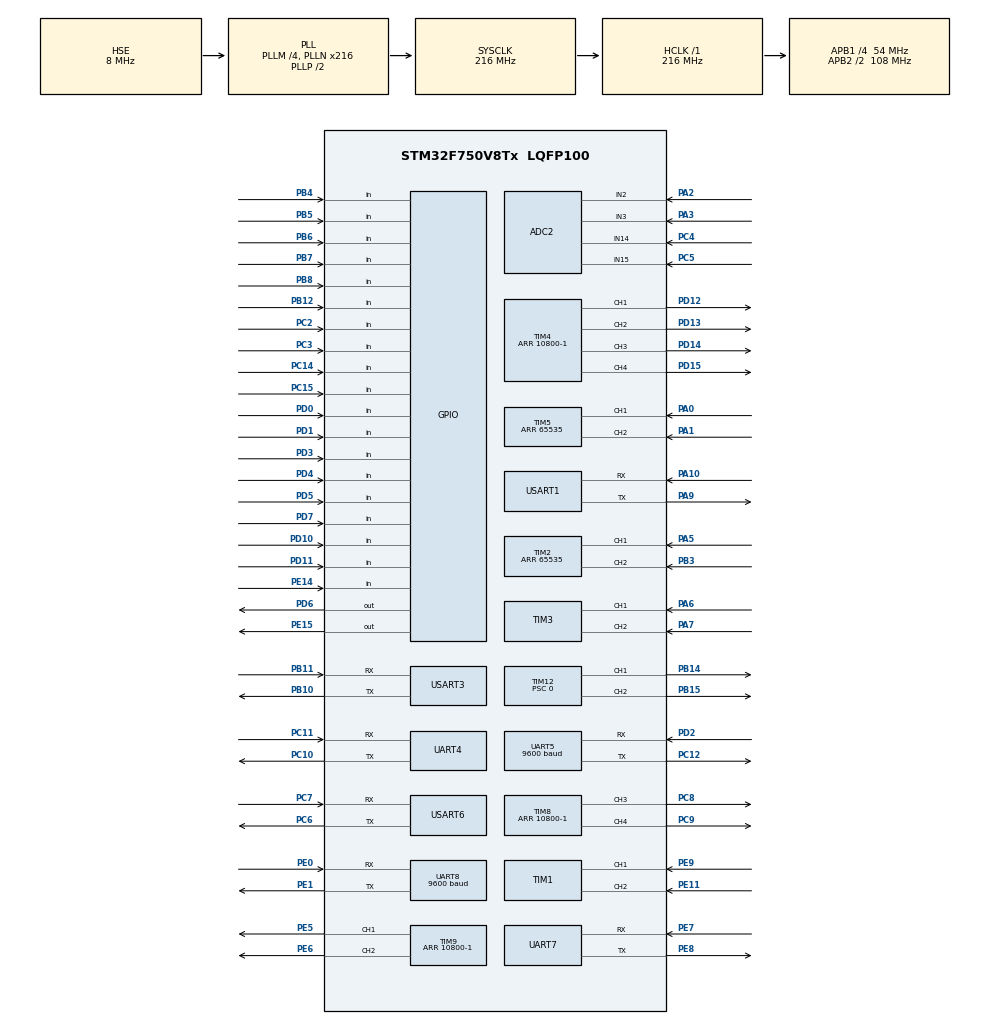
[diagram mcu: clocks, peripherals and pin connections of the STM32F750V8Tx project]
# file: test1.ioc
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ADC2.Channel-1\#ChannelRegularConversion=ADC_CHANNEL_2
ADC2.Channel-2\#ChannelRegularConversion=ADC_CHANNEL_3
ADC2.Channel-3\#ChannelRegularConversion=ADC_CHANNEL_14
ADC2.Channel-4\#ChannelRegularConversion=ADC_CHANNEL_15
ADC2.ContinuousConvMode=ENABLE
ADC2.DMAContinuousRequests=ENABLE
ADC2.NbrOfConversion=4
ADC2.NbrOfConversionFlag=1
ADC2.Rank-1\#ChannelRegularConversion=1
ADC2.Rank-2\#ChannelRegularConversion=2
ADC2.Rank-3\#ChannelRegularConversion=3
ADC2.Rank-4\#ChannelRegularConversion=4
ADC2.SamplingTime-1\#ChannelRegularConversion=ADC_SAMPLETIME_480CYCLES
ADC2.SamplingTime-2\#ChannelRegularConversion=ADC_SAMPLETIME_480CYCLES
ADC2.SamplingTime-3\#ChannelRegularConversion=ADC_SAMPLETIME_480CYCLES
ADC2.SamplingTime-4\#ChannelRegularConversion=ADC_SAMPLETIME_480CYCLES
CORTEX_M7.default_mode_Activation=1
Dma.ADC2.3.Direction=DMA_PERIPH_TO_MEMORY
Dma.ADC2.3.FIFOMode=DMA_FIFOMODE_DISABLE
Dma.ADC2.3.Instance=DMA2_Stream2
Dma.ADC2.3.MemDataAlignment=DMA_MDATAALIGN_HALFWORD
Dma.ADC2.3.MemInc=DMA_MINC_ENABLE
Dma.ADC2.3.Mode=DMA_CIRCULAR
Dma.ADC2.3.PeriphDataAlignment=DMA_PDATAALIGN_HALFWORD
Dma.ADC2.3.PeriphInc=DMA_PINC_DISABLE
Dma.ADC2.3.Priority=DMA_PRIORITY_VERY_HIGH
Dma.Request0=USART3_RX
Dma.Request1=UART4_RX
Dma.Request2=UART4_TX
Dma.Request3=ADC2
Dma.UART4_RX.1.Direction=DMA_PERIPH_TO_MEMORY
Dma.UART4_RX.1.FIFOMode=DMA_FIFOMODE_DISABLE
Dma.UART4_RX.1.Instance=DMA1_Stream2
Dma.UART4_RX.1.MemDataAlignment=DMA_MDATAALIGN_BYTE
Dma.UART4_RX.1.MemInc=DMA_MINC_ENABLE
Dma.UART4_RX.1.Mode=DMA_NORMAL
Dma.UART4_RX.1.PeriphDataAlignment=DMA_PDATAALIGN_BYTE
Dma.UART4_RX.1.PeriphInc=DMA_PINC_DISABLE
Dma.UART4_RX.1.Priority=DMA_PRIORITY_HIGH
Dma.UART4_TX.2.Direction=DMA_MEMORY_TO_PERIPH
Dma.UART4_TX.2.FIFOMode=DMA_FIFOMODE_DISABLE
Dma.UART4_TX.2.Instance=DMA1_Stream4
Dma.UART4_TX.2.MemDataAlignment=DMA_MDATAALIGN_BYTE
Dma.UART4_TX.2.MemInc=DMA_MINC_ENABLE
Dma.UART4_TX.2.Mode=DMA_NORMAL
Dma.UART4_TX.2.PeriphDataAlignment=DMA_PDATAALIGN_BYTE
Dma.UART4_TX.2.PeriphInc=DMA_PINC_DISABLE
Dma.UART4_TX.2.Priority=DMA_PRIORITY_LOW
Dma.USART3_RX.0.Direction=DMA_PERIPH_TO_MEMORY
Dma.USART3_RX.0.FIFOMode=DMA_FIFOMODE_DISABLE
Dma.USART3_RX.0.Instance=DMA1_Stream1
Dma.USART3_RX.0.MemDataAlignment=DMA_MDATAALIGN_BYTE
Dma.USART3_RX.0.MemInc=DMA_MINC_ENABLE
Dma.USART3_RX.0.Mode=DMA_NORMAL
Dma.USART3_RX.0.PeriphDataAlignment=DMA_PDATAALIGN_BYTE
Dma.USART3_RX.0.PeriphInc=DMA_PINC_DISABLE
Dma.USART3_RX.0.Priority=DMA_PRIORITY_HIGH
FREERTOS.INCLUDE_eTaskGetState=1
FREERTOS.INCLUDE_uxTaskGetStackHighWaterMark=1
FREERTOS.INCLUDE_vTaskDelayUntil=1
FREERTOS.Tasks01=defaultTask,0,256,StartDefaultTask,Default,NULL,Dynamic,NULL,NULL
Mcu.Family=STM32F7
Mcu.Name=STM32F750V8Tx
Mcu.Package=LQFP100
NVIC.DMA1_Stream1_IRQn=true\:5\:0\:false\:false\:true\:true\:false\:true\:true
NVIC.DMA1_Stream2_IRQn=true\:5\:0\:false\:false\:true\:true\:false\:true\:true
NVIC.DMA1_Stream4_IRQn=true\:5\:0\:false\:false\:true\:true\:false\:true\:true
NVIC.DMA2_Stream2_IRQn=true\:5\:0\:false\:false\:true\:true\:false\:true\:true
NVIC.PriorityGroup=NVIC_PRIORITYGROUP_4
NVIC.TIM1_BRK_TIM9_IRQn=true\:5\:0\:false\:false\:true\:true\:true\:true\:true
NVIC.TIM1_CC_IRQn=true\:5\:0\:false\:false\:true\:true\:true\:true\:true
NVIC.TIM1_TRG_COM_TIM11_IRQn=true\:5\:0\:false\:false\:true\:true\:true\:true\:true
NVIC.TIM1_UP_TIM10_IRQn=true\:5\:0\:false\:false\:true\:true\:true\:true\:true
NVIC.TIM2_IRQn=true\:5\:0\:false\:false\:true\:true\:true\:true\:true
NVIC.TIM3_IRQn=true\:5\:0\:false\:false\:true\:true\:true\:true\:true
NVIC.TIM4_IRQn=true\:5\:0\:false\:false\:true\:true\:true\:true\:true
NVIC.TIM8_BRK_TIM12_IRQn=true\:5\:0\:false\:false\:true\:true\:true\:true\:true
NVIC.TIM8_CC_IRQn=true\:5\:0\:false\:false\:true\:true\:true\:true\:true
NVIC.TIM8_TRG_COM_TIM14_IRQn=true\:15\:0\:false\:false\:true\:false\:false\:true\:true
NVIC.TIM8_UP_TIM13_IRQn=true\:5\:0\:false\:false\:true\:true\:true\:true\:true
NVIC.TimeBase=TIM8_TRG_COM_TIM14_IRQn
NVIC.TimeBaseIP=TIM14
NVIC.UART4_IRQn=true\:5\:0\:false\:false\:true\:true\:true\:true\:true
NVIC.UART5_IRQn=true\:5\:0\:false\:false\:true\:true\:true\:true\:true
NVIC.UART7_IRQn=true\:5\:0\:false\:false\:true\:true\:true\:true\:true
NVIC.UART8_IRQn=true\:5\:0\:false\:false\:true\:true\:true\:true\:true
NVIC.USART1_IRQn=true\:5\:0\:false\:false\:true\:true\:true\:true\:true
NVIC.USART3_IRQn=true\:5\:0\:false\:false\:true\:true\:true\:true\:true
NVIC.USART6_IRQn=true\:5\:0\:false\:false\:true\:true\:true\:true\:true
PA0/WKUP.Signal=S_TIM5_CH1
PA1.Signal=S_TIM5_CH2
PA10.Mode=Asynchronous
PA10.Signal=USART1_RX
PA13.Mode=Serial_Wire
PA13.Signal=SYS_JTMS-SWDIO
PA14.Mode=Serial_Wire
PA14.Signal=SYS_JTCK-SWCLK
PA2.Signal=ADCx_IN2
PA3.Signal=ADCx_IN3
PA5.Signal=S_TIM2_CH1_ETR
PA6.Signal=S_TIM3_CH1
PA7.Signal=S_TIM3_CH2
PA9.Mode=Asynchronous
PA9.Signal=USART1_TX
PB10.Mode=Asynchronous
PB10.Signal=USART3_TX
PB11.Mode=Asynchronous
PB11.Signal=USART3_RX
PB12.GPIO_PuPd=GPIO_PULLUP
PB12.Signal=GPIO_Input
PB14.Signal=S_TIM12_CH1
PB15.Signal=S_TIM12_CH2
PB3.Signal=S_TIM2_CH2
PB4.Signal=GPIO_Input
PB5.Signal=GPIO_Input
PB6.Signal=GPIO_Input
PB7.Signal=GPIO_Input
PB8.Signal=GPIO_Input
PC10.Mode=Asynchronous
PC10.Signal=UART4_TX
PC11.Mode=Asynchronous
PC11.Signal=UART4_RX
PC12.Mode=Asynchronous
PC12.Signal=UART5_TX
PC14/OSC32_IN.Signal=GPIO_Input
PC15/OSC32_OUT.Signal=GPIO_Input
PC2.Signal=GPIO_Input
PC3.Signal=GPIO_Input
PC4.Signal=ADCx_IN14
PC5.Signal=ADCx_IN15
PC6.Mode=Asynchronous
PC6.Signal=USART6_TX
PC7.Mode=Asynchronous
PC7.Signal=USART6_RX
PC8.Signal=S_TIM8_CH3
PC9.Signal=S_TIM8_CH4
PD0.Signal=GPIO_Input
PD1.Signal=GPIO_Input
PD10.Signal=GPIO_Input
PD11.Signal=GPIO_Input
PD12.Signal=S_TIM4_CH1
PD13.Signal=S_TIM4_CH2
PD14.Signal=S_TIM4_CH3
PD15.Signal=S_TIM4_CH4
PD2.Mode=Asynchronous
PD2.Signal=UART5_RX
PD3.Signal=GPIO_Input
PD4.Signal=GPIO_Input
PD5.Signal=GPIO_Input
PD6.Signal=GPIO_Output
PD7.Signal=GPIO_Input
PE0.Mode=Asynchronous
PE0.Signal=UART8_RX
PE1.Mode=Asynchronous
PE1.Signal=UART8_TX
PE11.Signal=S_TIM1_CH2
PE14.Signal=GPIO_Input
PE15.GPIO_ModeDefaultOutputPP=GPIO_MODE_OUTPUT_PP
PE15.GPIO_PuPd=GPIO_NOPULL
PE15.Signal=GPIO_Output
PE5.Signal=S_TIM9_CH1
PE6.Signal=S_TIM9_CH2
PE7.Mode=Asynchronous
PE7.Signal=UART7_RX
PE8.Mode=Asynchronous
PE8.Signal=UART7_TX
PE9.Signal=S_TIM1_CH1
PH0/OSC_IN.Mode=HSE-External-Oscillator
PH0/OSC_IN.Signal=RCC_OSC_IN
PH1/OSC_OUT.Mode=HSE-External-Oscillator
PH1/OSC_OUT.Signal=RCC_OSC_OUT
ProjectManager.HeapSize=0x200
ProjectManager.StackSize=0x400
ProjectManager.TargetToolchain=MDK-ARM V5.32
RCC.AHBFreq_Value=216000000
RCC.APB1CLKDivider=RCC_HCLK_DIV4
RCC.APB1Freq_Value=54000000
RCC.APB1TimFreq_Value=108000000
RCC.APB2CLKDivider=RCC_HCLK_DIV2
RCC.APB2Freq_Value=108000000
RCC.APB2TimFreq_Value=216000000
RCC.CortexFreq_Value=216000000
RCC.HCLKFreq_Value=216000000
RCC.HSE_VALUE=8000000
RCC.HSI_VALUE=16000000
RCC.LSE_VALUE=32768
RCC.PLLM=4
RCC.PLLN=216
RCC.PLLSourceVirtual=RCC_PLLSOURCE_HSE
RCC.SYSCLKFreq_VALUE=216000000
RCC.SYSCLKSource=RCC_SYSCLKSOURCE_PLLCLK
RCC.USBFreq_Value=216000000
RCC.VCOOutputFreq_Value=432000000
SH.ADCx_IN14.0=ADC2_IN14,IN14
SH.ADCx_IN15.0=ADC2_IN15,IN15
SH.ADCx_IN2.0=ADC2_IN2,IN2
SH.ADCx_IN3.0=ADC2_IN3,IN3
SH.S_TIM12_CH1.0=TIM12_CH1,PWM Generation1 CH1
SH.S_TIM12_CH2.0=TIM12_CH2,PWM Generation2 CH2
SH.S_TIM1_CH1.0=TIM1_CH1,Encoder_Interface
SH.S_TIM1_CH2.0=TIM1_CH2,Encoder_Interface
SH.S_TIM2_CH1_ETR.0=TIM2_CH1,Encoder_Interface
SH.S_TIM2_CH2.0=TIM2_CH2,Encoder_Interface
SH.S_TIM3_CH1.0=TIM3_CH1,Encoder_Interface
SH.S_TIM3_CH2.0=TIM3_CH2,Encoder_Interface
SH.S_TIM4_CH1.0=TIM4_CH1,PWM Generation1 CH1
SH.S_TIM4_CH2.0=TIM4_CH2,PWM Generation2 CH2
SH.S_TIM4_CH3.0=TIM4_CH3,PWM Generation3 CH3
SH.S_TIM4_CH4.0=TIM4_CH4,PWM Generation4 CH4
SH.S_TIM5_CH1.0=TIM5_CH1,Encoder_Interface
SH.S_TIM5_CH2.0=TIM5_CH2,Encoder_Interface
SH.S_TIM8_CH3.0=TIM8_CH3,PWM Generation3 CH3
SH.S_TIM8_CH4.0=TIM8_CH4,PWM Generation4 CH4
SH.S_TIM9_CH1.0=TIM9_CH1,PWM Generation1 CH1
SH.S_TIM9_CH2.0=TIM9_CH2,PWM Generation2 CH2
TIM1.AutoReloadPreload=TIM_AUTORELOAD_PRELOAD_ENABLE
TIM1.EncoderMode=TIM_ENCODERMODE_TI12
TIM11.AutoReloadPreload=TIM_AUTORELOAD_PRELOAD_ENABLE
TIM11.Period=21600-1
TIM11.Prescaler=10000-1
TIM12.AutoReloadPreload=TIM_AUTORELOAD_PRELOAD_ENABLE
TIM12.Channel-PWM\ Generation1\ CH1=TIM_CHANNEL_1
TIM12.Channel-PWM\ Generation2\ CH2=TIM_CHANNEL_2
TIM12.Period=10800-1
TIM12.Prescaler=0
TIM2.AutoReloadPreload=TIM_AUTORELOAD_PRELOAD_ENABLE
TIM2.EncoderMode=TIM_ENCODERMODE_TI12
TIM2.Period=65535
TIM3.AutoReloadPreload=TIM_AUTORELOAD_PRELOAD_ENABLE
TIM3.EncoderMode=TIM_ENCODERMODE_TI12
TIM4.AutoReloadPreload=TIM_AUTORELOAD_PRELOAD_ENABLE
TIM4.Channel-PWM\ Generation1\ CH1=TIM_CHANNEL_1
TIM4.Channel-PWM\ Generation2\ CH2=TIM_CHANNEL_2
TIM4.Channel-PWM\ Generation3\ CH3=TIM_CHANNEL_3
TIM4.Channel-PWM\ Generation4\ CH4=TIM_CHANNEL_4
TIM4.Period=10800-1
TIM5.AutoReloadPreload=TIM_AUTORELOAD_PRELOAD_ENABLE
TIM5.EncoderMode=TIM_ENCODERMODE_TI12
TIM5.Period=65535
TIM8.AutoReloadPreload=TIM_AUTORELOAD_PRELOAD_ENABLE
TIM8.Channel-PWM\ Generation3\ CH3=TIM_CHANNEL_3
TIM8.Channel-PWM\ Generation4\ CH4=TIM_CHANNEL_4
TIM8.Period=10800-1
TIM9.AutoReloadPreload=TIM_AUTORELOAD_PRELOAD_ENABLE
TIM9.Channel-PWM\ Generation1\ CH1=TIM_CHANNEL_1
TIM9.Channel-PWM\ Generation2\ CH2=TIM_CHANNEL_2
TIM9.Period=10800-1
UART5.BaudRate=9600
UART8.BaudRate=9600
USART1.VirtualMode-Asynchronous=VM_ASYNC
USART3.VirtualMode-Asynchronous=VM_ASYNC
USART6.VirtualMode=VM_ASYNC
VP_FREERTOS_VS_CMSIS_V1.Mode=CMSIS_V1
VP_SYS_VS_tim14.Mode=TIM14
VP_TIM11_VS_ClockSourceINT.Mode=Enable_Timer
VP_TIM4_VS_ClockSourceINT.Mode=Internal
VP_TIM8_VS_ClockSourceINT.Mode=Internal
VP_TIM9_VS_ClockSourceINT.Mode=Internal
board=custom

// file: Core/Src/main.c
/* USER CODE BEGIN Header */
/**
  ******************************************************************************
  * @file           : main.c
  * @brief          : Main program body
  ******************************************************************************
  * @attention
  *
  * Copyright (c) 2026 STMicroelectronics.
  * All rights reserved.
  *
  * This software is licensed under terms that can be found in the LICENSE file
  * in the root directory of this software component.
  * If no LICENSE file comes with this software, it is provided AS-IS.
  *
  ******************************************************************************
  */
/* USER CODE END Header */
#include "main.h"
#include "cmsis_os.h"
#include "adc.h"
#include "dma.h"
#include "tim.h"
#include "usart.h"
#include "gpio.h"

/* USER CODE BEGIN Includes */
//////��ʱ
#include "motor_task.h"
#include "motor.h"
#include "stdio.h"

/* USER CODE END Includes */

void SystemClock_Config(void);
static void MPU_Config(void);
void MX_FREERTOS_Init(void);

int main(void)
{

  /* MPU Configuration--------------------------------------------------------*/
  MPU_Config();

  /* MCU Configuration--------------------------------------------------------*/

  /* Reset of all peripherals, Initializes the Flash interface and the Systick. */
  HAL_Init();

  /* Configure the system clock */
  SystemClock_Config();

  /* Initialize all configured peripherals */
  MX_GPIO_Init();
  MX_DMA_Init();
  MX_TIM4_Init();
  MX_TIM8_Init();
  MX_TIM9_Init();
  MX_USART3_UART_Init();
  MX_TIM1_Init();
  MX_TIM2_Init();
  MX_TIM3_Init();
  MX_TIM5_Init();
  MX_TIM11_Init();
  MX_UART5_Init();
  MX_UART8_Init();
  MX_TIM12_Init();
  MX_UART7_Init();
  MX_UART4_Init();
  MX_USART1_UART_Init();
  MX_ADC2_Init();
  MX_USART6_UART_Init();

  /* Call init function for freertos objects (in cmsis_os2.c) */
  MX_FREERTOS_Init();

  /* Start scheduler */
  osKernelStart();

  /* We should never get here as control is now taken by the scheduler */

  /* Infinite loop */
  while (1)
  {

  }
}

void SystemClock_Config(void)
{
  RCC_OscInitTypeDef RCC_OscInitStruct = {0};
  RCC_ClkInitTypeDef RCC_ClkInitStruct = {0};

  /** Configure the main internal regulator output voltage
  */
  __HAL_RCC_PWR_CLK_ENABLE();
  __HAL_PWR_VOLTAGESCALING_CONFIG(PWR_REGULATOR_VOLTAGE_SCALE1);

  /** Initializes the RCC Oscillators according to the specified parameters
  * in the RCC_OscInitTypeDef structure.
  */
  RCC_OscInitStruct.OscillatorType = RCC_OSCILLATORTYPE_HSE;
  RCC_OscInitStruct.HSEState = RCC_HSE_ON;
  RCC_OscInitStruct.PLL.PLLState = RCC_PLL_ON;
  RCC_OscInitStruct.PLL.PLLSource = RCC_PLLSOURCE_HSE;
  RCC_OscInitStruct.PLL.PLLM = 4;
  RCC_OscInitStruct.PLL.PLLN = 216;
  RCC_OscInitStruct.PLL.PLLP = RCC_PLLP_DIV2;
  RCC_OscInitStruct.PLL.PLLQ = 2;
  if (HAL_RCC_OscConfig(&RCC_OscInitStruct) != HAL_OK)
  {
    Error_Handler();
  }

  /** Activate the Over-Drive mode
  */
  if (HAL_PWREx_EnableOverDrive() != HAL_OK)
  {
    Error_Handler();
  }

  /** Initializes the CPU, AHB and APB buses clocks
  */
  RCC_ClkInitStruct.ClockType = RCC_CLOCKTYPE_HCLK|RCC_CLOCKTYPE_SYSCLK
                              |RCC_CLOCKTYPE_PCLK1|RCC_CLOCKTYPE_PCLK2;
  RCC_ClkInitStruct.SYSCLKSource = RCC_SYSCLKSOURCE_PLLCLK;
  RCC_ClkInitStruct.AHBCLKDivider = RCC_SYSCLK_DIV1;
  RCC_ClkInitStruct.APB1CLKDivider = RCC_HCLK_DIV4;
  RCC_ClkInitStruct.APB2CLKDivider = RCC_HCLK_DIV2;

  if (HAL_RCC_ClockConfig(&RCC_ClkInitStruct, FLASH_LATENCY_7) != HAL_OK)
  {
    Error_Handler();
  }
}

 /* MPU Configuration */

void MPU_Config(void)
{
  MPU_Region_InitTypeDef MPU_InitStruct = {0};

  /* Disables the MPU */
  HAL_MPU_Disable();

  /** Initializes and configures the Region and the memory to be protected
  */
  MPU_InitStruct.Enable = MPU_REGION_ENABLE;
  MPU_InitStruct.Number = MPU_REGION_NUMBER0;
  MPU_InitStruct.BaseAddress = 0x0;
  MPU_InitStruct.Size = MPU_REGION_SIZE_4GB;
  MPU_InitStruct.SubRegionDisable = 0x87;
  MPU_InitStruct.TypeExtField = MPU_TEX_LEVEL0;
  MPU_InitStruct.AccessPermission = MPU_REGION_NO_ACCESS;
  MPU_InitStruct.DisableExec = MPU_INSTRUCTION_ACCESS_DISABLE;
  MPU_InitStruct.IsShareable = MPU_ACCESS_SHAREABLE;
  MPU_InitStruct.IsCacheable = MPU_ACCESS_NOT_CACHEABLE;
  MPU_InitStruct.IsBufferable = MPU_ACCESS_NOT_BUFFERABLE;

  HAL_MPU_ConfigRegion(&MPU_InitStruct);
  /* Enables the MPU */
  HAL_MPU_Enable(MPU_PRIVILEGED_DEFAULT);

}

//void HAL_TIM_PeriodElapsedCallback(TIM_HandleTypeDef *htim)
//{
//  /* USER CODE BEGIN Callback 0 */
//////////////////	//TODO
//  /* USER CODE END Callback 0 */
//  if (htim->Instance == TIM14)
//  {
//    HAL_IncTick();
//  }
//  /* USER CODE BEGIN Callback 1 */

//  /* USER CODE END Callback 1 */
//}

void Error_Handler(void)
{
  __disable_irq();
  while (1)
  {
  }
}

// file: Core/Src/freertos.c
/* USER CODE BEGIN Header */
/**
  ******************************************************************************
  * File Name          : freertos.c
  * Description        : Code for freertos applications
  ******************************************************************************
  * @attention
  *
  * Copyright (c) 2026 STMicroelectronics.
  * All rights reserved.
  *
  * This software is licensed under terms that can be found in the LICENSE file
  * in the root directory of this software component.
  * If no LICENSE file comes with this software, it is provided AS-IS.
  *
  ******************************************************************************
  */
/* USER CODE END Header */

#include "FreeRTOS.h"
#include "task.h"
#include "main.h"
#include "cmsis_os.h"

/* USER CODE BEGIN Includes */
#include "stdio.h"
#include "usart.h"
#include "motor_task.h"
#include "motor.h"
#include "temporary_task.h"
#include "task_create.h"

/* USER CODE END Includes */

osThreadId defaultTaskHandle;

void StartDefaultTask(void const * argument);

void MX_FREERTOS_Init(void); /* (MISRA C 2004 rule 8.1) */

/* GetIdleTaskMemory prototype (linked to static allocation support) */
void vApplicationGetIdleTaskMemory( StaticTask_t **ppxIdleTaskTCBBuffer, StackType_t **ppxIdleTaskStackBuffer, uint32_t *pulIdleTaskStackSize );

/* USER CODE BEGIN GET_IDLE_TASK_MEMORY */
static StaticTask_t xIdleTaskTCBBuffer;
static StackType_t xIdleStack[configMINIMAL_STACK_SIZE];

void vApplicationGetIdleTaskMemory( StaticTask_t **ppxIdleTaskTCBBuffer, StackType_t **ppxIdleTaskStackBuffer, uint32_t *pulIdleTaskStackSize )
{
  *ppxIdleTaskTCBBuffer = &xIdleTaskTCBBuffer;
  *ppxIdleTaskStackBuffer = &xIdleStack[0];
  *pulIdleTaskStackSize = configMINIMAL_STACK_SIZE;
  /* place for user code */
}
/* USER CODE END GET_IDLE_TASK_MEMORY */

void MX_FREERTOS_Init(void) {

  /* Create the thread(s) */
  /* definition and creation of defaultTask */
  osThreadDef(defaultTask, StartDefaultTask, osPriorityNormal, 0, 256);
  defaultTaskHandle = osThreadCreate(osThread(defaultTask), NULL);

}

void StartDefaultTask(void const * argument)
{
  /* USER CODE BEGIN StartDefaultTask */
  /* Infinite loop */
	Start_task_create();
	vTaskDelete(NULL);//任务自删
  for(;;)
  {
		//printf("delete failed");
    osDelay(1000);
  }
  /* USER CODE END StartDefaultTask */
}
